# HDSC_HC32F4A0 register map
Vendor: HDSC; Series: ARMCM4; File version: 1.0
CPU: CM4 r0p1, little endian, MPU, FPU, 4 interrupt priority bits
Registers are 32-bit, read-write, reset 0x0 unless marked. A register's access mark holds for its fields unless they carry their own. Offsets are from the block's base; [hi:lo] are bit positions; {n}, {i} and the like mark numbered series; 'fields as' and 'values as' point back to an identical list.

## TMR41 — desc TMR4
Base 0x40038000
Same registers: TMR42 0x40038400, TMR43 0x40038800
0x02 OCCRUH 16-bit
0x06 OCCRUL 16-bit
0x0A OCCRVH 16-bit
0x0E OCCRVL 16-bit
0x12 OCCRWH 16-bit
0x16 OCCRWL 16-bit
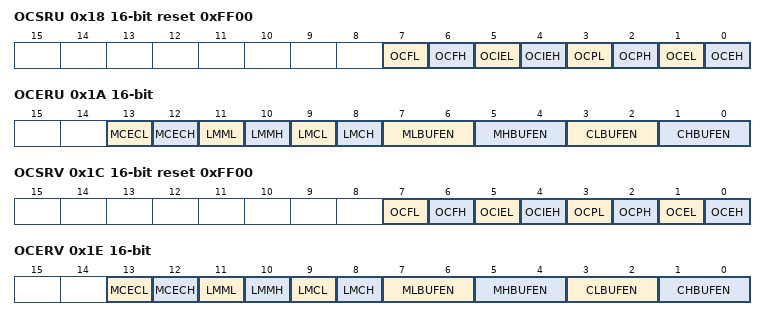
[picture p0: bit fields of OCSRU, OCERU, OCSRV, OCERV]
0x18 OCSRU 16-bit reset 0xFF00
  [7] OCFL, [6] OCFH, [5] OCIEL, [4] OCIEH, [3] OCPL, [2] OCPH, [1] OCEL, [0] OCEH
0x1A OCERU 16-bit
  [13] MCECL, [12] MCECH, [11] LMML, [10] LMMH, [9] LMCL, [8] LMCH, [7:6] MLBUFEN, [5:4] MHBUFEN, [3:2] CLBUFEN, [1:0] CHBUFEN
0x1C OCSRV 16-bit reset 0xFF00
  fields as OCSRU
0x1E OCERV 16-bit
  fields as OCERU
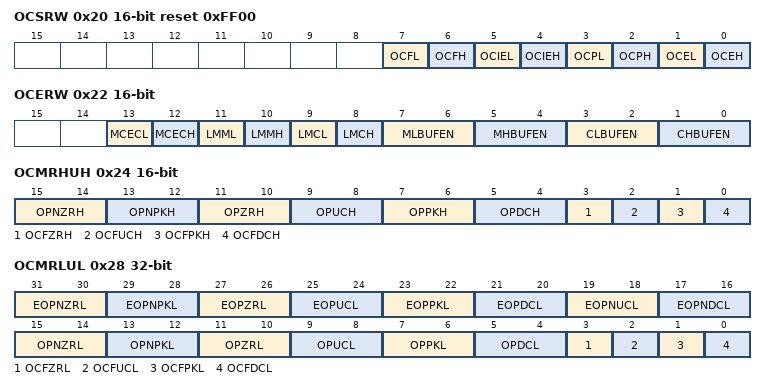
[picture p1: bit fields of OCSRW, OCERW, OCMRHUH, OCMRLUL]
0x20 OCSRW 16-bit reset 0xFF00
  fields as OCSRU
0x22 OCERW 16-bit
  fields as OCERU
0x24 OCMRHUH 16-bit
  [15:14] OPNZRH, [13:12] OPNPKH, [11:10] OPZRH, [9:8] OPUCH, [7:6] OPPKH, [5:4] OPDCH, [3] OCFZRH, [2] OCFUCH, [1] OCFPKH, [0] OCFDCH
0x28 OCMRLUL
  [31:30] EOPNZRL, [29:28] EOPNPKL, [27:26] EOPZRL, [25:24] EOPUCL, [23:22] EOPPKL, [21:20] EOPDCL, [19:18] EOPNUCL, [17:16] EOPNDCL, [15:14] OPNZRL, [13:12] OPNPKL, [11:10] OPZRL, [9:8] OPUCL, [7:6] OPPKL, [5:4] OPDCL, [3] OCFZRL, [2] OCFUCL, [1] OCFPKL, [0] OCFDCL
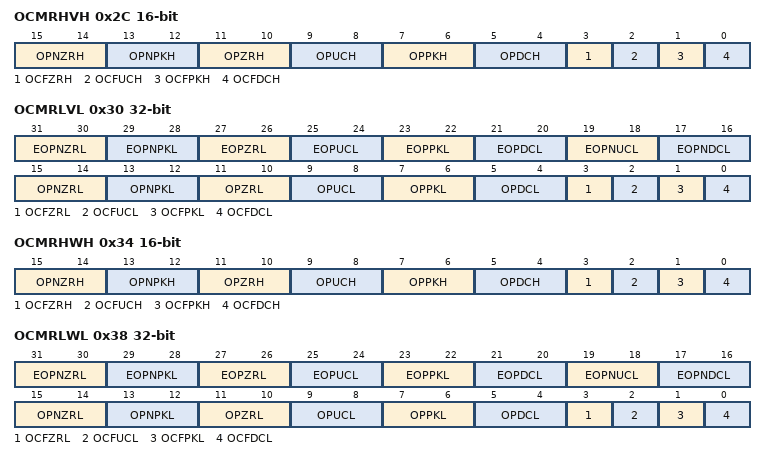
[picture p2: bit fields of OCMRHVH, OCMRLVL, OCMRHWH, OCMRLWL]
0x2C OCMRHVH 16-bit
  fields as OCMRHUH
0x30 OCMRLVL
  fields as OCMRLUL
0x34 OCMRHWH 16-bit
  fields as OCMRHUH
0x38 OCMRLWL
  fields as OCMRLUL
0x42 CPSR 16-bit reset 0xFFFF
0x46 CNTR 16-bit
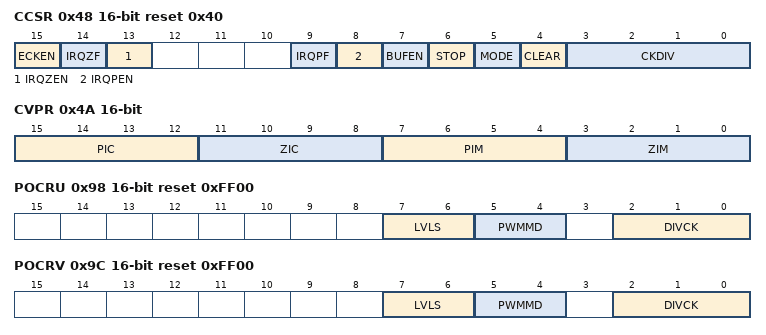
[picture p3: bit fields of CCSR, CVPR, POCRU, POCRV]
0x48 CCSR 16-bit reset 0x40
  [15] ECKEN, [14] IRQZF, [13] IRQZEN, [9] IRQPF, [8] IRQPEN, [7] BUFEN, [6] STOP, [5] MODE, [4] CLEAR, [3:0] CKDIV
0x4A CVPR 16-bit
  [15:12] PIC ro, [11:8] ZIC ro, [7:4] PIM, [3:0] ZIM
0x82 PFSRU 16-bit
0x84 PDARU 16-bit
0x86 PDBRU 16-bit
0x8A PFSRV 16-bit
0x8C PDARV 16-bit
0x8E PDBRV 16-bit
0x92 PFSRW 16-bit
0x94 PDARW 16-bit
0x96 PDBRW 16-bit
0x98 POCRU 16-bit reset 0xFF00
  [7:6] LVLS, [5:4] PWMMD, [2:0] DIVCK
0x9C POCRV 16-bit reset 0xFF00
  [7:6] LVLS, [5:4] PWMMD, [2:0] DIVCK
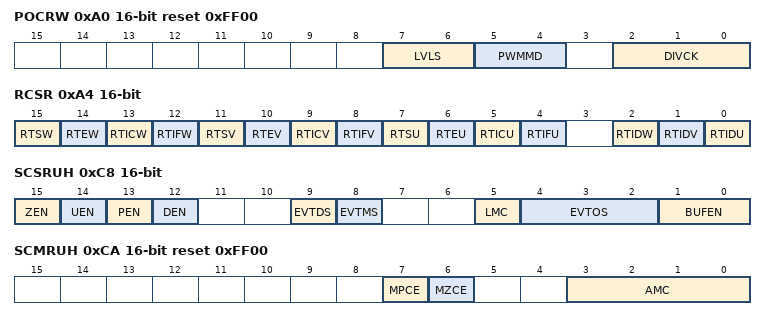
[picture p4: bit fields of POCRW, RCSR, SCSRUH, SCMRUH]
0xA0 POCRW 16-bit reset 0xFF00
  [7:6] LVLS, [5:4] PWMMD, [2:0] DIVCK
0xA4 RCSR 16-bit
  [15] RTSW, [14] RTEW, [13] RTICW, [12] RTIFW ro, [11] RTSV, [10] RTEV, [9] RTICV, [8] RTIFV ro, [7] RTSU, [6] RTEU, [5] RTICU, [4] RTIFU ro, [2] RTIDW, [1] RTIDV, [0] RTIDU
0xB2 SCCRUH 16-bit
0xB6 SCCRUL 16-bit
0xBA SCCRVH 16-bit
0xBE SCCRVL 16-bit
0xC2 SCCRWH 16-bit
0xC6 SCCRWL 16-bit
0xC8 SCSRUH 16-bit
  [15] ZEN, [14] UEN, [13] PEN, [12] DEN, [9] EVTDS, [8] EVTMS, [5] LMC, [4:2] EVTOS, [1:0] BUFEN
0xCA SCMRUH 16-bit reset 0xFF00
  [7] MPCE, [6] MZCE, [3:0] AMC
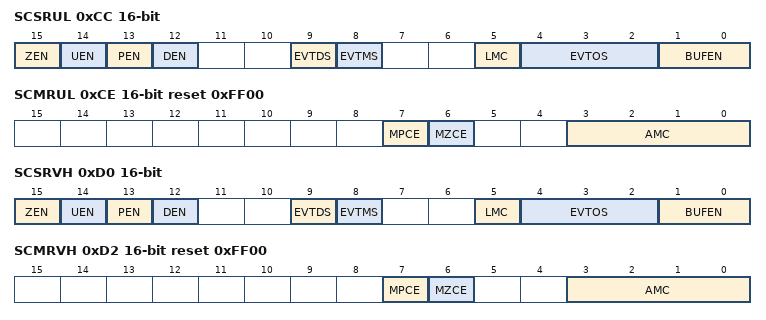
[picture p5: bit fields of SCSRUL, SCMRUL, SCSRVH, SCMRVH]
0xCC SCSRUL 16-bit
  fields as SCSRUH
0xCE SCMRUL 16-bit reset 0xFF00
  [7] MPCE, [6] MZCE, [3:0] AMC
0xD0 SCSRVH 16-bit
  fields as SCSRUH
0xD2 SCMRVH 16-bit reset 0xFF00
  [7] MPCE, [6] MZCE, [3:0] AMC
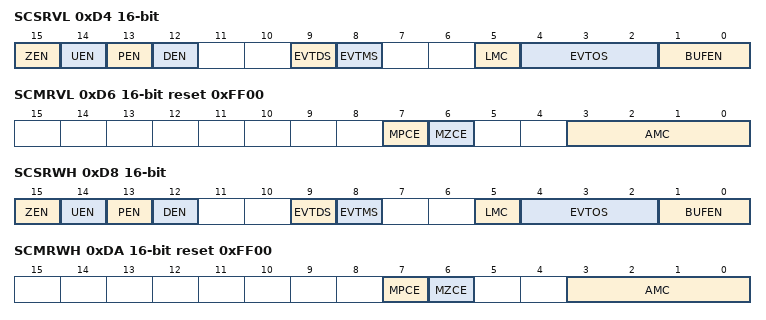
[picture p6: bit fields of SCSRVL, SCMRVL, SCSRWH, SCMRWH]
0xD4 SCSRVL 16-bit
  fields as SCSRUH
0xD6 SCMRVL 16-bit reset 0xFF00
  [7] MPCE, [6] MZCE, [3:0] AMC
0xD8 SCSRWH 16-bit
  fields as SCSRUH
0xDA SCMRWH 16-bit reset 0xFF00
  [7] MPCE, [6] MZCE, [3:0] AMC
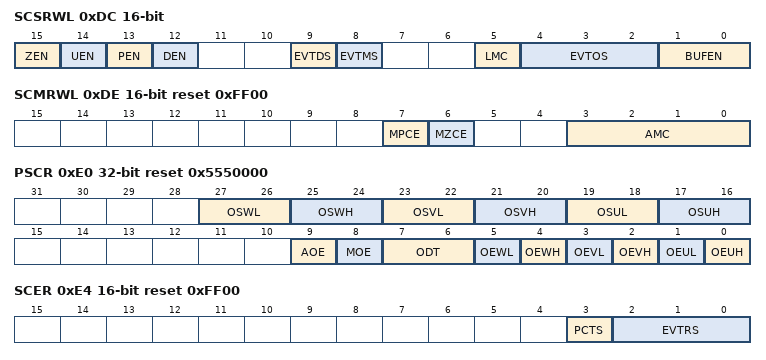
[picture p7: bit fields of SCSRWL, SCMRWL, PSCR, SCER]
0xDC SCSRWL 16-bit
  fields as SCSRUH
0xDE SCMRWL 16-bit reset 0xFF00
  [7] MPCE, [6] MZCE, [3:0] AMC
0xE0 PSCR reset 0x5550000
  [27:26] OSWL, [25:24] OSWH, [23:22] OSVL, [21:20] OSVH, [19:18] OSUL, [17:16] OSUH, [9] AOE, [8] MOE, [7:6] ODT, [5] OEWL, [4] OEWH, [3] OEVL, [2] OEVH, [1] OEUL, [0] OEUH
0xE4 SCER 16-bit reset 0xFF00
  [3] PCTS, [2:0] EVTRS

## TMR61 — desc TMR6
Base 0x40018000
Same registers: TMR62 0x40018400, TMR63 0x40018800, TMR64 0x40018C00, TMR65 0x40019000, TMR66 0x40019400, TMR67 0x40019800, TMR68 0x40019C00
0x00 CNTER
0x04 UPDAR
0x40 PERAR reset 0xFFFFFFFF
0x44 PERBR reset 0xFFFFFFFF
0x48 PERCR reset 0xFFFFFFFF
0x80 GCMAR reset 0xFFFFFFFF
0x84 GCMBR reset 0xFFFFFFFF
0x88 GCMCR reset 0xFFFFFFFF
0x8C GCMDR reset 0xFFFFFFFF
0x90 GCMER reset 0xFFFFFFFF
0x94 GCMFR reset 0xFFFFFFFF
0xC0 SCMAR reset 0xFFFFFFFF
0xC4 SCMBR reset 0xFFFFFFFF
0xC8 SCMCR reset 0xFFFFFFFF
0xCC SCMDR reset 0xFFFFFFFF
0xD0 SCMER reset 0xFFFFFFFF
0xD4 SCMFR reset 0xFFFFFFFF
0x100 DTUAR reset 0xFFFFFFFF
0x104 DTDAR reset 0xFFFFFFFF
0x108 DTUBR reset 0xFFFFFFFF
0x10C DTDBR reset 0xFFFFFFFF
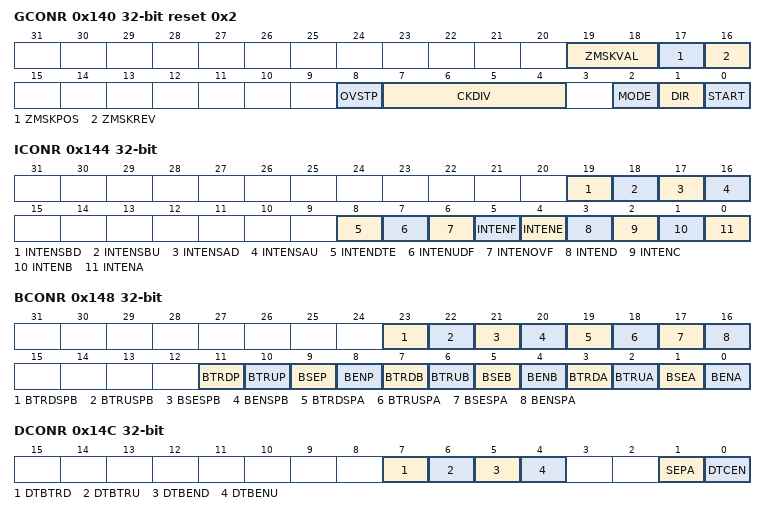
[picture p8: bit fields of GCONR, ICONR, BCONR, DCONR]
0x140 GCONR reset 0x2
  [19:18] ZMSKVAL, [17] ZMSKPOS, [16] ZMSKREV, [8] OVSTP, [7:4] CKDIV, [2] MODE, [1] DIR, [0] START
0x144 ICONR
  [19] INTENSBD, [18] INTENSBU, [17] INTENSAD, [16] INTENSAU, [8] INTENDTE, [7] INTENUDF, [6] INTENOVF, [5] INTENF, [4] INTENE, [3] INTEND, [2] INTENC, [1] INTENB, [0] INTENA
0x148 BCONR
  [23] BTRDSPB, [22] BTRUSPB, [21] BSESPB, [20] BENSPB, [19] BTRDSPA, [18] BTRUSPA, [17] BSESPA, [16] BENSPA, [11] BTRDP, [10] BTRUP, [9] BSEP, [8] BENP, [7] BTRDB, [6] BTRUB, [5] BSEB, [4] BENB, [3] BTRDA, [2] BTRUA, [1] BSEA, [0] BENA
0x14C DCONR
  [7] DTBTRD, [6] DTBTRU, [5] DTBEND, [4] DTBENU, [1] SEPA, [0] DTCEN
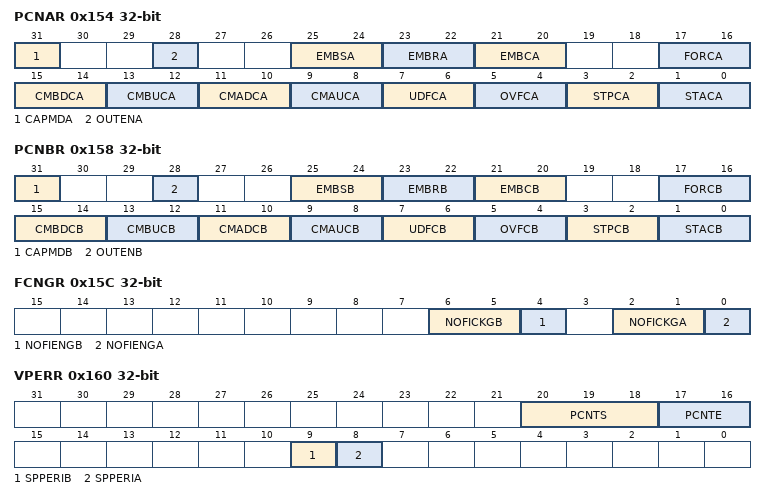
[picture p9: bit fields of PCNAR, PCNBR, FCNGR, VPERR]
0x154 PCNAR
  [31] CAPMDA, [28] OUTENA, [25:24] EMBSA, [23:22] EMBRA, [21:20] EMBCA, [17:16] FORCA, [15:14] CMBDCA, [13:12] CMBUCA, [11:10] CMADCA, [9:8] CMAUCA, [7:6] UDFCA, [5:4] OVFCA, [3:2] STPCA, [1:0] STACA
0x158 PCNBR
  [31] CAPMDB, [28] OUTENB, [25:24] EMBSB, [23:22] EMBRB, [21:20] EMBCB, [17:16] FORCB, [15:14] CMBDCB, [13:12] CMBUCB, [11:10] CMADCB, [9:8] CMAUCB, [7:6] UDFCB, [5:4] OVFCB, [3:2] STPCB, [1:0] STACB
0x15C FCNGR
  [6:5] NOFICKGB, [4] NOFIENGB, [2:1] NOFICKGA, [0] NOFIENGA
0x160 VPERR
  [20:18] PCNTS, [17:16] PCNTE, [9] SPPERIB, [8] SPPERIA
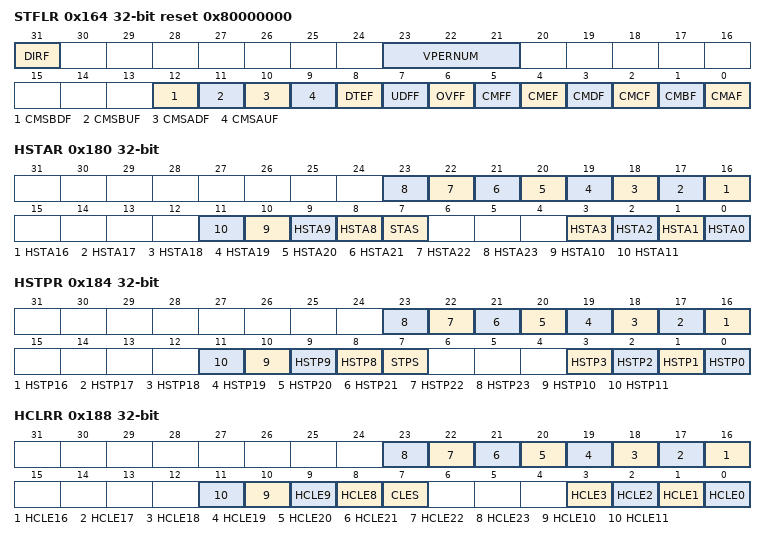
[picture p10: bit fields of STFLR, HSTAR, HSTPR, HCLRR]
0x164 STFLR reset 0x80000000
  [31] DIRF ro, [23:21] VPERNUM ro, [12] CMSBDF, [11] CMSBUF, [10] CMSADF, [9] CMSAUF, [8] DTEF ro, [7] UDFF, [6] OVFF, [5] CMFF, [4] CMEF, [3] CMDF, [2] CMCF, [1] CMBF, [0] CMAF
0x180 HSTAR
  [n] HSTA{n} (n=16..23), [n] HSTA{n} (n=8..11), [7] STAS, [n] HSTA{n} (n=0..3)
0x184 HSTPR
  [n] HSTP{n} (n=16..23), [n] HSTP{n} (n=8..11), [7] STPS, [n] HSTP{n} (n=0..3)
0x188 HCLRR
  [n] HCLE{n} (n=16..23), [n] HCLE{n} (n=8..11), [7] CLES, [n] HCLE{n} (n=0..3)
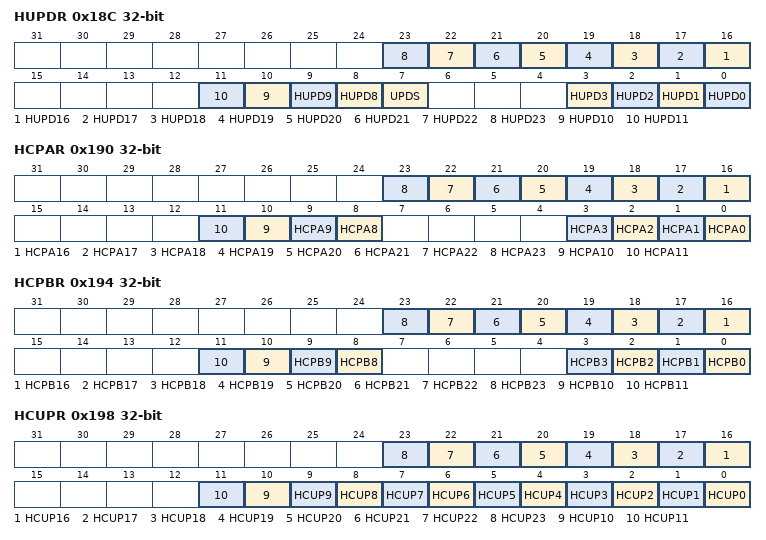
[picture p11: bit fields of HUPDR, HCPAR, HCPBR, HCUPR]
0x18C HUPDR
  [n] HUPD{n} (n=16..23), [n] HUPD{n} (n=8..11), [7] UPDS, [n] HUPD{n} (n=0..3)
0x190 HCPAR
  [n] HCPA{n} (n=16..23), [n] HCPA{n} (n=8..11), [n] HCPA{n} (n=0..3)
0x194 HCPBR
  [n] HCPB{n} (n=16..23), [n] HCPB{n} (n=8..11), [n] HCPB{n} (n=0..3)
0x198 HCUPR
  [n] HCUP{n} (n=16..23), [n] HCUP{n} (n=0..11)
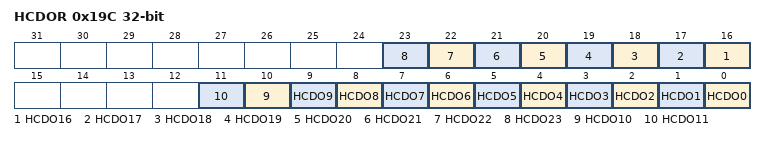
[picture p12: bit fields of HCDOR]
0x19C HCDOR
  [n] HCDO{n} (n=16..23), [n] HCDO{n} (n=0..11)
